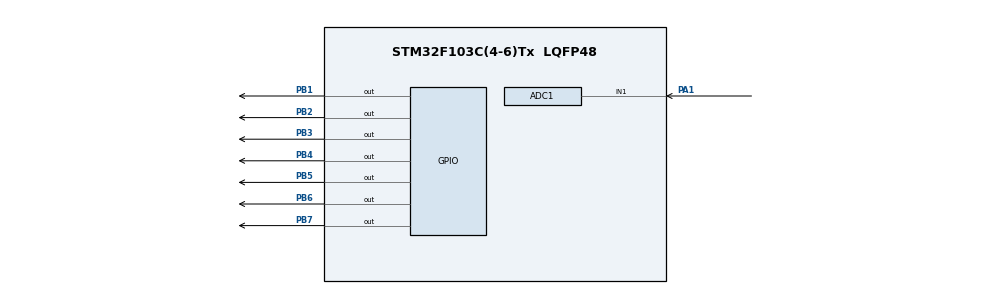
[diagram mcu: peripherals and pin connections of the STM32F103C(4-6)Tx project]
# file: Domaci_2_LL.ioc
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ADC1.Channel-0\#ChannelRegularConversion=ADC_CHANNEL_1
ADC1.ContinuousConvMode=ENABLE
ADC1.NbrOfConversionFlag=1
ADC1.Rank-0\#ChannelRegularConversion=1
ADC1.SamplingTime-0\#ChannelRegularConversion=ADC_SAMPLETIME_1CYCLE_5
ADC1.master=1
Mcu.Family=STM32F1
Mcu.Name=STM32F103C(4-6)Tx
Mcu.Package=LQFP48
NVIC.PriorityGroup=NVIC_PRIORITYGROUP_4
PA1.Signal=ADCx_IN1
PB1.Signal=GPIO_Output
PB2.Signal=GPIO_Output
PB3.Signal=GPIO_Output
PB4.Signal=GPIO_Output
PB5.Signal=GPIO_Output
PB6.Signal=GPIO_Output
PB7.Signal=GPIO_Output
PD0-OSC_IN.Mode=HSE-External-Oscillator
PD0-OSC_IN.Signal=RCC_OSC_IN
PD1-OSC_OUT.Mode=HSE-External-Oscillator
PD1-OSC_OUT.Signal=RCC_OSC_OUT
ProjectManager.HeapSize=0x200
ProjectManager.StackSize=0x400
ProjectManager.TargetToolchain=STM32CubeIDE
RCC.APB1Freq_Value=8000000
RCC.APB2Freq_Value=8000000
SH.ADCx_IN1.0=ADC1_IN1,IN1
board=custom

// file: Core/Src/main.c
/* USER CODE BEGIN Header */
/**
  ******************************************************************************
  * @file           : main.c
  * @brief          : Main program body
  ******************************************************************************
  * @attention
  *
  * Copyright (c) 2023 STMicroelectronics.
  * All rights reserved.
  *
  * This software is licensed under terms that can be found in the LICENSE file
  * in the root directory of this software component.
  * If no LICENSE file comes with this software, it is provided AS-IS.
  *
  ******************************************************************************
  */
/* USER CODE END Header */
#include "main.h"

//Lazar Lazarevic: 14 * 5 = 70
float zeljena_temp=70;
int epruvete[]={3,1,4,1,0,3,1,4,1,0,2,3,0,3};
int kutija[14];
int brojac_kutija = 0;
float trenutna_temp;
int velicina_niza = sizeof(epruvete) / sizeof(epruvete[0]);
uint16_t rez;
int pokretna_traka = 50; //mm
int pomeraj_trake = 5; //mm

/*Moje Ime i Prezime sacinjava 15 slova, kako pun krug ima 360 stepeni,
 *epruvete ce se nalaziti na 25.71 stepena pomeraja motora.
 *Jedan impuls motor okrene za 1.8 stepen sto znaci da je potrebno 14.28
 *impulsa kako bi motor pomerio epruvete za po jedno mesto.
 *Kako bih mogao da simuliram sa celim brojevima usvojicu da je 14 impulsa
 *potrebno kako bi motor pomerio epruvete za po jedno mesto.
 *
 */
int pomeraj_epruvete = 14;

ADC_HandleTypeDef hadc1;

void SystemClock_Config(void);
static void MX_GPIO_Init(void);
static void MX_ADC1_Init(void);

int main(void)
{
  /* USER CODE BEGIN 1 */
	// Funkcija za rotaciju niza u desno za određeni broj koraka

  /* USER CODE END 1 */

  /* MCU Configuration--------------------------------------------------------*/

  /* Reset of all peripherals, Initializes the Flash interface and the Systick. */
  HAL_Init();

  /* Configure the system clock */
  SystemClock_Config();

  /* Initialize all configured peripherals */
  MX_GPIO_Init();
  MX_ADC1_Init();

  /* Infinite loop */
  while (1)
  {
	  HAL_ADC_Start(&hadc1);
	  HAL_ADC_PollForConversion(&hadc1, 100);
	  rez = HAL_ADC_GetValue(&hadc1);
	  trenutna_temp = (1.5*rez/4096)*100;

	  while(trenutna_temp < zeljena_temp){
	  	//ukljucujemo motor M1, okretanje u smeru kazaljke na satu
		  for (int i = 0; i < pomeraj_epruvete; i++) {
		      HAL_GPIO_WritePin(GPIOB, GPIO_PIN_3, GPIO_PIN_SET); // Enable
		      HAL_Delay(0.000005); //Enable mora biti ispred Direction minimalno 5µs
		      HAL_GPIO_WritePin(GPIOB, GPIO_PIN_2, GPIO_PIN_SET); // Direction=1, smer kazaljke
		      HAL_Delay(0.000005); //Direction mora biti ispred Impulsa minimalno 5µs
		      HAL_GPIO_WritePin(GPIOB, GPIO_PIN_1, GPIO_PIN_SET); // Impulse
		      HAL_Delay(0.0000025); //Minimalna sirina visokog nivoa ne sme biti manja od 2.5µs
		      HAL_GPIO_WritePin(GPIOB, GPIO_PIN_1, GPIO_PIN_RESET); // Impulse
		      HAL_Delay(0.0000025); //Minimalna sirina niskog nivoa ne sme biti manja od 2.5µs
		  }
		    //kada se motor pomerio za 14 impulsa sada treba rotirati pozicije epruveta
		    // Čuvanje vrednosti poslednjeg elementa
	        int temp = epruvete[velicina_niza - 1];
	        // Pomeranje svih elemenata u desno
	        for (int i = velicina_niza - 1; i > 0; i--) {
	        	epruvete[i] = epruvete[i - 1];
	        }
	        // Postavljanje čuvane vrednosti na prvo mesto
	        epruvete[0] = temp;
	  }

	  //Zaustavljanje motora M1, epruvete zagrejane do zeljene temperature
	  HAL_GPIO_WritePin(GPIOB, GPIO_PIN_3, GPIO_PIN_RESET); //

	  // Biranje epruvete koju zelimo:
	  // 0 , 1, 2, 3, 4
	  int uneti_broj = 0;

	  int indeks_pocetak = -1;
	  int indeks_kraj = -1;

	    for (int i = 0; i < velicina_niza; ++i) {
	        if (epruvete[i] == uneti_broj) {
	            indeks_pocetak = i;
	            break;
	        }
	    }

	    // Pretraga niza od kraja
	    int k = 1;  // Pomeranje indeksa od desne strane
	    for (int i = velicina_niza - 1; i >= 0; --i) {
	        if (epruvete[i] == uneti_broj) {
	            indeks_kraj = k;
	            break;
	        }
	        k++;
	    }

	    //funlcije koje ce rotirati elemente niza na osnovu pomeranja motora

	    // Funkcija za rotaciju niza u desno za određeni broj koraka
		void rotateRight(int arr[], int n, int steps) {
		    int temp;
		    for (int i = 0; i < steps; ++i) {
		        temp = arr[n - 1];
		        for (int j = n - 1; j > 0; --j) {
		            arr[j] = arr[j - 1];
		        }
		        arr[0] = temp;
		    }
		}

		// Funkcija za rotaciju niza u levo za određeni broj koraka
		void rotateLeft(int arr[], int n, int steps) {
		    int temp;
		    for (int i = 0; i < steps; ++i) {
		        temp = arr[0];
		        for (int j = 0; j < n - 1; ++j) {
		            arr[j] = arr[j + 1];
		        }
		        arr[n - 1] = temp;
		    }
		}

	    // Ispis rezultata
	    if (indeks_pocetak != -1 && indeks_kraj != -1) {
	        if (indeks_pocetak <= indeks_kraj) {
	            printf("Motor 1 se okreće u desno za %d koraka\n", indeks_pocetak);
	            //za pomeraj epruvete za 1 korak potrebno je dovesti 14 impulsa, okrece se u desno
	            for (int i = 0; i < pomeraj_epruvete * indeks_pocetak ; i++) {
	  		         HAL_GPIO_WritePin(GPIOB, GPIO_PIN_3, GPIO_PIN_SET); // Enable
	  		         HAL_Delay(0.000005); //Enable mora biti ispred Direction minimalno 5µs
	  		         HAL_GPIO_WritePin(GPIOB, GPIO_PIN_2, GPIO_PIN_SET); // Direction=1, motor se okrece u desno
	  		         HAL_Delay(0.000005); //Direction mora biti ispred Impulsa minimalno 5µs
	  		         HAL_GPIO_WritePin(GPIOB, GPIO_PIN_1, GPIO_PIN_SET); // Impulse
	  		         HAL_Delay(0.0000025); //Minimalna sirina visokog nivoa ne sme biti manja od 2.5µs
	  		         HAL_GPIO_WritePin(GPIOB, GPIO_PIN_1, GPIO_PIN_RESET); // Impulse
	  		         HAL_Delay(0.0000025); //Minimalna sirina niskog nivoa ne sme biti manja od 2.5µs
	            }
	        //Motor 1 se okrenuo udesno potreban broj impulsa i doveo je epruvetu na zeljeno mesto
	        HAL_GPIO_WritePin(GPIOB, GPIO_PIN_3, GPIO_PIN_RESET);
	        //stanje epruveta(niza) nakon okretanja motora
	        rotateLeft(epruvete, velicina_niza, indeks_pocetak);

	        } else {
	            printf("Motor 1 se okreće u levo za %d koraka\n", indeks_kraj);
	            //za pomeraj epruvete za 1 korak potrebno je dovesti 14 impulsa, okrece se u levo
	            for (int i = 0; i < pomeraj_epruvete * indeks_kraj ; i++) {
	  		         HAL_GPIO_WritePin(GPIOB, GPIO_PIN_3, GPIO_PIN_SET); // Enable
	  		         HAL_Delay(0.000005); //Enable mora biti ispred Direction minimalno 5µs
	  		         HAL_GPIO_WritePin(GPIOB, GPIO_PIN_2, GPIO_PIN_RESET); // Direction=0, motor se okrece u levo
	  		         HAL_Delay(0.000005); //Direction mora biti ispred Impulsa minimalno 5µs
	  		         HAL_GPIO_WritePin(GPIOB, GPIO_PIN_1, GPIO_PIN_SET); // Impulse
	  		         HAL_Delay(0.0000025); //Minimalna sirina visokog nivoa ne sme biti manja od 2.5µs
	  		         HAL_GPIO_WritePin(GPIOB, GPIO_PIN_1, GPIO_PIN_RESET); // Impulse
	  		         HAL_Delay(0.0000025); //Minimalna sirina niskog nivoa ne sme biti manja od 2.5µs
	       	    }
	        //Motor 1 se okrenuo ulevo potreban broj impulsa i doveo je epruvetu na zeljeno mesto
	        HAL_GPIO_WritePin(GPIOB, GPIO_PIN_3, GPIO_PIN_RESET);
	        //stanje epruveta(niza) nakon okretanja motora
	        rotateRight(epruvete, velicina_niza, indeks_kraj);
	        }

	        // Ispis niza nakon pomeranja
	        printf("Niz nakon pomeranja: ");
	        for (int i = 0; i < velicina_niza; ++i) {
	            printf("%d ", epruvete[i]);
	        }
	        printf("\n");

	    } else {
	        printf("Broj %d nije pronađen u nizu.\n", uneti_broj);
	    }

	    /* Kada smo dosli ovde epruveta stoji na mestu odakle ce je pokretna traka odvesti u kutiju
	     * simuliranje uzimanja eprivete cemo izvrsiti tako sto cemo je smestiti u niz kutija
	     *
	     */

	    //pokretanje Motora 2, koji ima zadatak da pomera traku
	    /*Da bi se motor okrenuo za jedan korak potrebno mu je 14 step signala
	     * posto je traka 50mm a jedan korak okrene traku za 5mm
	     * potrebno je da se napravi 50/5 koraka  * 14 step signala
	     */
	    for (int i = 0; i < pomeraj_epruvete*(pokretna_traka/pomeraj_trake) ; i++) {
		       HAL_GPIO_WritePin(GPIOB, GPIO_PIN_6, GPIO_PIN_SET); // Enable
		       HAL_Delay(0.000005); //Enable mora biti ispred Direction minimalno 5µs
		       HAL_GPIO_WritePin(GPIOB, GPIO_PIN_5, GPIO_PIN_SET); // Direction=1, pretpostavka da traka okretanjem u desno prenosi epruvete
	           HAL_Delay(0.000005); //Direction mora biti ispred Impulsa minimalno 5µs
		       HAL_GPIO_WritePin(GPIOB, GPIO_PIN_4, GPIO_PIN_SET); // Impulse
		       HAL_Delay(0.0000025); //Minimalna sirina visokog nivoa ne sme biti manja od 2.5µs
		       HAL_GPIO_WritePin(GPIOB, GPIO_PIN_4, GPIO_PIN_RESET); // Impulse
		       HAL_Delay(0.0000025); //Minimalna sirina niskog nivoa ne sme biti manja od 2.5µs
	    }
	           HAL_GPIO_WritePin(GPIOB, GPIO_PIN_6, GPIO_PIN_RESET); // Zaustavljamo Moror2

	           // Premestanje nultog elementa u kutiju
	           kutija[brojac_kutija] = epruvete[0];
	           brojac_kutija++;

	           // Postavljanje vrednosti 404 na mesto nultog elementa
	           epruvete[0] = 404;

	           // Prikazivanje elemenata u kutiji
	           printf("\nElementi u kutiji: ");
	           for (int i = 0; i < brojac_kutija; i++) {
	               printf("%d ", kutija[i]);
	           }

  }
}

void SystemClock_Config(void)
{
  RCC_OscInitTypeDef RCC_OscInitStruct = {0};
  RCC_ClkInitTypeDef RCC_ClkInitStruct = {0};
  RCC_PeriphCLKInitTypeDef PeriphClkInit = {0};

  /** Initializes the RCC Oscillators according to the specified parameters
  * in the RCC_OscInitTypeDef structure.
  */
  RCC_OscInitStruct.OscillatorType = RCC_OSCILLATORTYPE_HSI;
  RCC_OscInitStruct.HSIState = RCC_HSI_ON;
  RCC_OscInitStruct.HSICalibrationValue = RCC_HSICALIBRATION_DEFAULT;
  RCC_OscInitStruct.PLL.PLLState = RCC_PLL_NONE;
  if (HAL_RCC_OscConfig(&RCC_OscInitStruct) != HAL_OK)
  {
    Error_Handler();
  }

  /** Initializes the CPU, AHB and APB buses clocks
  */
  RCC_ClkInitStruct.ClockType = RCC_CLOCKTYPE_HCLK|RCC_CLOCKTYPE_SYSCLK
                              |RCC_CLOCKTYPE_PCLK1|RCC_CLOCKTYPE_PCLK2;
  RCC_ClkInitStruct.SYSCLKSource = RCC_SYSCLKSOURCE_HSI;
  RCC_ClkInitStruct.AHBCLKDivider = RCC_SYSCLK_DIV1;
  RCC_ClkInitStruct.APB1CLKDivider = RCC_HCLK_DIV1;
  RCC_ClkInitStruct.APB2CLKDivider = RCC_HCLK_DIV1;

  if (HAL_RCC_ClockConfig(&RCC_ClkInitStruct, FLASH_LATENCY_0) != HAL_OK)
  {
    Error_Handler();
  }
  PeriphClkInit.PeriphClockSelection = RCC_PERIPHCLK_ADC;
  PeriphClkInit.AdcClockSelection = RCC_ADCPCLK2_DIV2;
  if (HAL_RCCEx_PeriphCLKConfig(&PeriphClkInit) != HAL_OK)
  {
    Error_Handler();
  }
}

static void MX_ADC1_Init(void)
{

  ADC_ChannelConfTypeDef sConfig = {0};

  /** Common config
  */
  hadc1.Instance = ADC1;
  hadc1.Init.ScanConvMode = ADC_SCAN_DISABLE;
  hadc1.Init.ContinuousConvMode = ENABLE;
  hadc1.Init.DiscontinuousConvMode = DISABLE;
  hadc1.Init.ExternalTrigConv = ADC_SOFTWARE_START;
  hadc1.Init.DataAlign = ADC_DATAALIGN_RIGHT;
  hadc1.Init.NbrOfConversion = 1;
  if (HAL_ADC_Init(&hadc1) != HAL_OK)
  {
    Error_Handler();
  }

  /** Configure Regular Channel
  */
  sConfig.Channel = ADC_CHANNEL_1;
  sConfig.Rank = ADC_REGULAR_RANK_1;
  sConfig.SamplingTime = ADC_SAMPLETIME_1CYCLE_5;
  if (HAL_ADC_ConfigChannel(&hadc1, &sConfig) != HAL_OK)
  {
    Error_Handler();
  }

}

static void MX_GPIO_Init(void)
{
  GPIO_InitTypeDef GPIO_InitStruct = {0};

  /* GPIO Ports Clock Enable */
  __HAL_RCC_GPIOD_CLK_ENABLE();
  __HAL_RCC_GPIOA_CLK_ENABLE();
  __HAL_RCC_GPIOB_CLK_ENABLE();

  /*Configure GPIO pin Output Level */
  HAL_GPIO_WritePin(GPIOB, GPIO_PIN_1|GPIO_PIN_2|GPIO_PIN_3|GPIO_PIN_4
                          |GPIO_PIN_5|GPIO_PIN_6|GPIO_PIN_7, GPIO_PIN_RESET);

  /*Configure GPIO pins : PB1 PB2 PB3 PB4
                           PB5 PB6 PB7 */
  GPIO_InitStruct.Pin = GPIO_PIN_1|GPIO_PIN_2|GPIO_PIN_3|GPIO_PIN_4
                          |GPIO_PIN_5|GPIO_PIN_6|GPIO_PIN_7;
  GPIO_InitStruct.Mode = GPIO_MODE_OUTPUT_PP;
  GPIO_InitStruct.Pull = GPIO_NOPULL;
  GPIO_InitStruct.Speed = GPIO_SPEED_FREQ_LOW;
  HAL_GPIO_Init(GPIOB, &GPIO_InitStruct);

}

void Error_Handler(void)
{
  __disable_irq();
  while (1)
  {
  }
}
